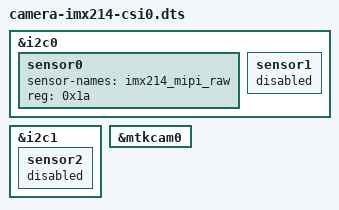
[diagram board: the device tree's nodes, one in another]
// SPDX-License-Identifier: GPL-2.0
/*
 * Copyright (c) 2022 MediaTek Inc.
 *
 */

/dts-v1/;
/plugin/;

#include "camera-common.dtsi"

/ {
	fragment@9 {
		target = <&i2c0>;
		__overlay__ {
			sensor0 {
				sensor-names = "imx214_mipi_raw";
				reg = <0x1a>;
				status = "okay";
			};
			sensor1 {
				status = "disabled";
			};
		};
	};

	fragment@10 {
		target = <&i2c1>;
		__overlay__ {
			sensor2 {
				status = "disabled";
			};
		};
	};

	fragment@11 {
		target = <&mtkcam0>;
		__overlay__ {
			status = "okay";
		};
	};
};
